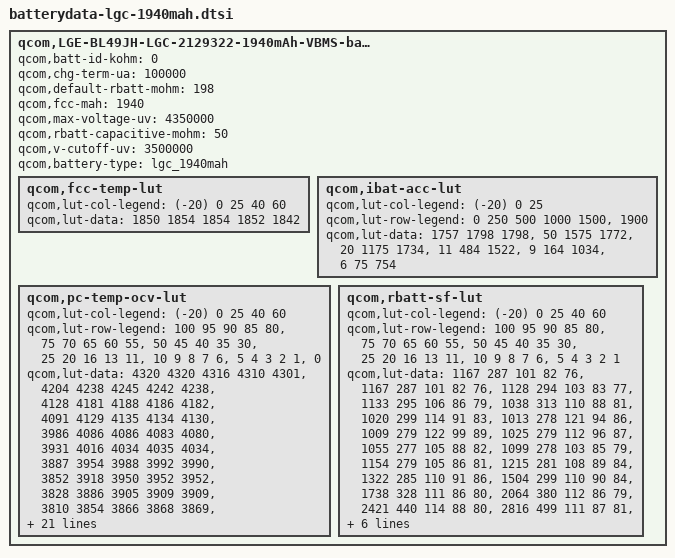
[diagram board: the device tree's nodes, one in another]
/* Copyright (c) 2014, The Linux Foundation. All rights reserved.
 *
 * This program is free software; you can redistribute it and/or modify
 * it under the terms of the GNU General Public License version 2 and
 * only version 2 as published by the Free Software Foundation.
 *
 * This program is distributed in the hope that it will be useful,
 * but WITHOUT ANY WARRANTY; without even the implied warranty of
 * MERCHANTABILITY or FITNESS FOR A PARTICULAR PURPOSE.  See the
 * GNU General Public License for more details.
 */
qcom,LGE-BL49JH-LGC-2129322-1940mAh-VBMS-batterydata {
	qcom,batt-id-kohm = <0>;
	qcom,chg-term-ua = <100000>;
	qcom,default-rbatt-mohm = <198>;
	qcom,fcc-mah = <1940>;
	qcom,max-voltage-uv = <4350000>;
	qcom,rbatt-capacitive-mohm = <50>;
	qcom,v-cutoff-uv = <3500000>;
	qcom,battery-type = "lgc_1940mah";

	qcom,fcc-temp-lut {
		qcom,lut-col-legend = <(-20) 0 25 40 60>;
		qcom,lut-data = <1850 1854 1854 1852 1842>;
	};

	qcom,ibat-acc-lut {
		qcom,lut-col-legend = <(-20) 0 25>;
		qcom,lut-row-legend = <0 250 500 1000 1500>,
					<1900>;
		qcom,lut-data = <1757 1798 1798>,
				<50 1575 1772>,
				<20 1175 1734>,
				<11 484 1522>,
				<9 164 1034>,
				<6 75 754>;
	};

	qcom,pc-temp-ocv-lut {
		qcom,lut-col-legend = <(-20) 0 25 40 60>;
		qcom,lut-row-legend = <100 95 90 85 80>,
					<75 70 65 60 55>,
					<50 45 40 35 30>,
					<25 20 16 13 11>,
					<10 9 8 7 6>,
					<5 4 3 2 1>,
					<0>;
		qcom,lut-data = <4320 4320 4316 4310 4301>,
				<4204 4238 4245 4242 4238>,
				<4128 4181 4188 4186 4182>,
				<4091 4129 4135 4134 4130>,
				<3986 4086 4086 4083 4080>,
				<3931 4016 4034 4035 4034>,
				<3887 3954 3988 3992 3990>,
				<3852 3918 3950 3952 3952>,
				<3828 3886 3905 3909 3909>,
				<3810 3854 3866 3868 3869>,
				<3795 3826 3838 3838 3838>,
				<3780 3802 3815 3816 3816>,
				<3764 3781 3797 3798 3797>,
				<3748 3763 3782 3782 3781>,
				<3728 3746 3768 3766 3760>,
				<3704 3731 3754 3748 3735>,
				<3676 3719 3732 3726 3712>,
				<3650 3712 3710 3704 3690>,
				<3627 3704 3696 3688 3676>,
				<3608 3696 3690 3682 3670>,
				<3598 3688 3688 3681 3668>,
				<3586 3682 3687 3680 3667>,
				<3572 3670 3682 3674 3660>,
				<3555 3658 3677 3668 3647>,
				<3535 3639 3656 3646 3626>,
				<3510 3612 3618 3608 3588>,
				<3476 3574 3572 3559 3538>,
				<3429 3522 3510 3497 3474>,
				<3358 3444 3428 3416 3394>,
				<3242 3319 3304 3288 3265>,
				<3000 3000 3000 3000 3000>;
	};

	qcom,rbatt-sf-lut {
		qcom,lut-col-legend = <(-20) 0 25 40 60>;
		qcom,lut-row-legend = <100 95 90 85 80>,
					<75 70 65 60 55>,
					<50 45 40 35 30>,
					<25 20 16 13 11>,
					<10 9 8 7 6>,
					<5 4 3 2 1>;
		qcom,lut-data = <1167 287 101 82 76>,
				<1167 287 101 82 76>,
				<1128 294 103 83 77>,
				<1133 295 106 86 79>,
				<1038 313 110 88 81>,
				<1020 299 114 91 83>,
				<1013 278 121 94 86>,
				<1009 279 122 99 89>,
				<1025 279 112 96 87>,
				<1055 277 105 88 82>,
				<1099 278 103 85 79>,
				<1154 279 105 86 81>,
				<1215 281 108 89 84>,
				<1322 285 110 91 86>,
				<1504 299 110 90 84>,
				<1738 328 111 86 80>,
				<2064 380 112 86 79>,
				<2421 440 114 88 80>,
				<2816 499 111 87 81>,
				<3124 534 114 89 82>,
				<3306 549 118 91 83>,
				<3487 565 122 94 84>,
				<3711 567 129 95 85>,
				<3951 568 135 96 84>,
				<3897 499 126 92 83>,
				<4148 507 122 91 83>,
				<4822 539 124 94 85>,
				<5813 577 130 99 90>,
				<7614 630 144 110 99>,
				<14373 821 183 144 126>;
	};
};
